# psoc6_01 register map
Vendor: Cypress Semiconductor; Series: PSoC6_01; File version: 1.0
CPU: CM4 r0p1, little endian, MPU, FPU, VTOR, 3 interrupt priority bits
Registers are 32-bit, read-write, reset 0x0 unless marked. A register's access mark holds for its fields unless they carry their own. Offsets are from the block's base; [hi:lo] are bit positions; {n}, {i} and the like mark numbered series; 'fields as' and 'values as' point back to an identical list.

## SCB0 (part 2 of 2) — Serial Communications Block (SPI/UART/I2C)
Base 0x40610000
Same registers: SCB{n} {0x40610000+0x10000*n} (n=1..8)
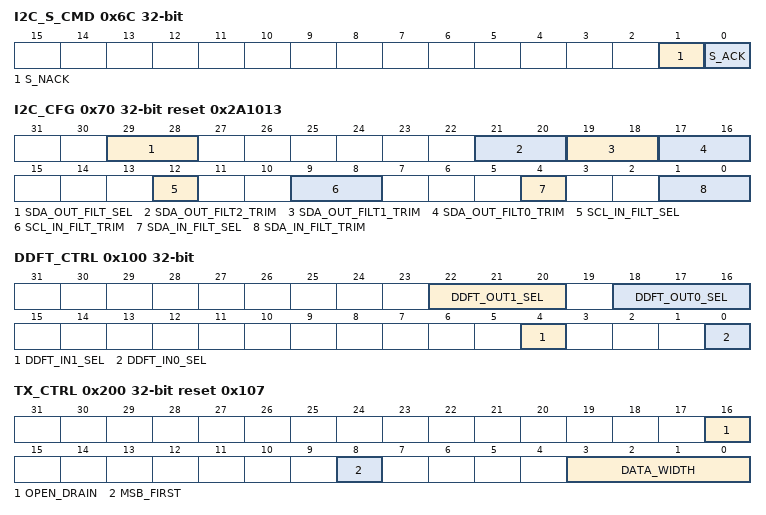
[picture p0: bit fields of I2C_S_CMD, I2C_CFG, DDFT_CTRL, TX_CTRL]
0x6C I2C_S_CMD — I2C slave command
  [1] S_NACK — When '1', attempt to transmit a negative acknowledgement (NACK). When this action is performed, the hardware sets this field to '0'. In EZ and CMD_RESP mode, this field should be set to '0' (it is only to be used in FIFO mode). This command has a higher priority than I2C_S_CMD.S_ACK, I2C_CTRL.S_READY_ADDR_ACK or I2C_CTRL.S_READY_DATA_ACK.
  [0] S_ACK — When '1', attempt to transmit an acknowledgement (ACK). When this action is performed, the hardware sets this field to '0'. In EZ and CMD_RESP mode, this field should be set to '0' (it is only to be used in FIFO mode).
0x70 I2C_CFG reset 0x2A1013 — I2C configuration
  [29:28] SDA_OUT_FILT_SEL
  [21:20] SDA_OUT_FILT2_TRIM — Trim bits for 'i2c_sda_out' 50 ns filter 2. Not to be modified by the user
  [19:18] SDA_OUT_FILT1_TRIM — Trim bits for 'i2c_sda_out' 50 ns filter 1. Not to be modified by the user
  [17:16] SDA_OUT_FILT0_TRIM — Trim bits for 'i2c_sda_out' 50 ns filter 0. Not to be modified by the user
  [12] SCL_IN_FILT_SEL
  [9:8] SCL_IN_FILT_TRIM — Trim bits for 'i2c_scl_in' 50 ns filter. Not to be modified by the user
  [4] SDA_IN_FILT_SEL
  [1:0] SDA_IN_FILT_TRIM — Trim bits for 'i2c_sda_in' 50 ns filter. SDA_IN_FILT_TRIM[1] is used to enable I2CS_EC or SPIS_EC access to internal EZ memory. 1: enable clk_scb 0: disable clk_scb Before going to deepsleep this field should be set to 0. It should be re-enabled once the device is awoken and clk_hf[0] is at the desired frequency.
0x100 DDFT_CTRL — Digital DfT control
  [22:20] DDFT_OUT1_SEL — Specifies signal that is connected to 'ddft_out[1]' (digital DfT output signal 1): In I2C mode (CTRL.MODE=0), '0': Constant '0'. '1': 'clk_ff_sram'. '2': 'rst_i2c_n'. '3': 'rst_i2c_stop_n'. '4': 'i2c_sda_in_qual'. '5': 'i2c_sda_out'. '6': 'event_i2c_ec_wake_up_ddft' from I2CS_IC '7': Undefined. In SPI mode (CTRL.MODE=1), '0': Constant '0'. '1': 'spi_start_detect' '2': 'spi_stop_detect' '3'-'7': Undefined.
  [18:16] DDFT_OUT0_SEL — Specifies signal that is connected to 'ddft_out[0]' (digital DfT output signal 0): In I2C mode (CTRL.MODE=0), '0': Constant '0'. '1': 'ec_busy_pp'. '2': 'rst_i2c_start_stop_n'. '3': 'rst_i2c_start_stop_n'. '4': 'i2c_scl_in_qual'. '5': 'i2c_sda_out_prel'. '6'-'7': Undefined. in SPI mode (CTRL.MODE=1), '0': Constant '0'. '1': 'rst_spi_n' '2': 'rst_spi_stop_n' '3'-'7': Undefined.
  [4] DDFT_IN1_SEL — Specifies signal that is connected to 'ddft_in[1]' (digital DfT input signal 0): '0': not used '1': used as 'i2c_sda_in' in I2C mode, as 'spi_mosi_in' in SPI mode
  [0] DDFT_IN0_SEL — Specifies signal that is connected to 'ddft_in[0]' (digital DfT input signal 0): '0': not used '1': used as 'i2c_scl_in' in I2C mode, as 'spi_clk_in' in SPI mode
0x200 TX_CTRL reset 0x107 — Transmitter control
  [16] OPEN_DRAIN — Each IO cell 'xxx' has two associated SCB output signals 'xxx_out_en' and 'xxx_out'. This field determines how the SCB controls those two signals. Consult the GPIO chapter in the architecture TRM to understand how the pin drive modes behave when connected to SCBs. '0': Normal operation mode. In this operation mode 'xxx_out_en' output enable signal is typically constant '1' the 'xxx_out' output is the outputted value. In other words, in normal operation mode, the 'xxx_out' output is used to control the IO cell output value: 'xxx_out' is '0' to drive an IO cell output value of '0' and 'xxx_out' is '1' to drive an IO cell output value of '1'. '1': Open drain operation mode. In this operation mode 'xxx_out_en' output controls the outputted value. Typically the 'xxx_out' signal is a constant '0'. Thus when 'xxx_out_en' is '1' the line is driven low, but when 'xxx_out_en' is '0' the output is not driven. This requires that the line is driven high by an external device or pull-up resistor The open drain mode is supported for: - I2C mode this field must be set. - UART mode use this mode when a pull-up resistor is used on the TX line. - SPI mode this field must be set if there are multiple slaves driving MISO.
  [8] MSB_FIRST — Least significant bit first ('0') or most significant bit first ('1'). For I2C, this field should be '1'. For EZ and CMD_RESP this field must be set to '1'
  [3:0] DATA_WIDTH — Dataframe width. DATA_WIDTH + 1 is the amount of bits in a transmitted data frame. This number does not include start, parity and stop bits. For UART mode, the valid range is [3, 8]. For SPI, the valid range is [3, 15]. For I2C the only valid value is 7. In EZ and CMD_RESP mode (for both SPI and I2C), the only valid value is 7.
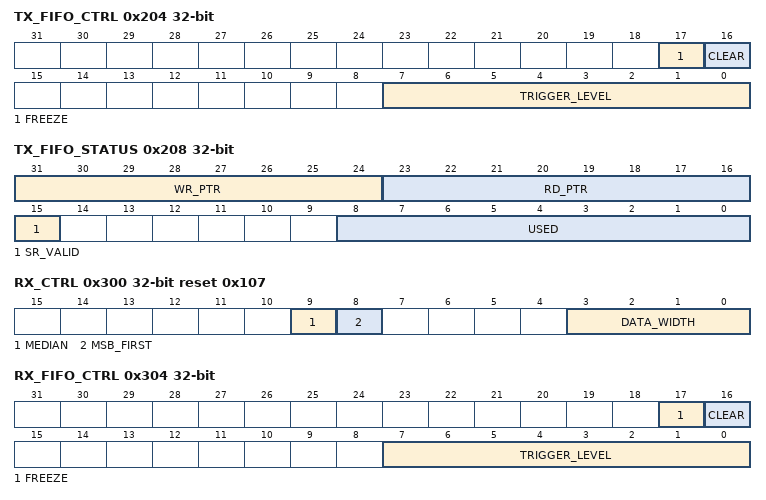
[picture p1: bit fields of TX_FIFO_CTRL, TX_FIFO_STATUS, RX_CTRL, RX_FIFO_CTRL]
0x204 TX_FIFO_CTRL — Transmitter FIFO control
  [17] FREEZE, [16] CLEAR, [7:0] TRIGGER_LEVEL
0x208 TX_FIFO_STATUS ro — Transmitter FIFO status
  [31:24] WR_PTR, [23:16] RD_PTR, [15] SR_VALID, [8:0] USED
0x240 TX_FIFO_WR wo — Transmitter FIFO write
  [15:0] DATA
0x300 RX_CTRL reset 0x107 — Receiver control
  [9] MEDIAN
  [8] MSB_FIRST — Least significant bit first ('0') or most significant bit first ('1'). For I2C, this field should be '1'. For EZ and CMD_RESP this field must be set to '1'
  [3:0] DATA_WIDTH
0x304 RX_FIFO_CTRL — Receiver FIFO control
  [17] FREEZE, [16] CLEAR, [7:0] TRIGGER_LEVEL
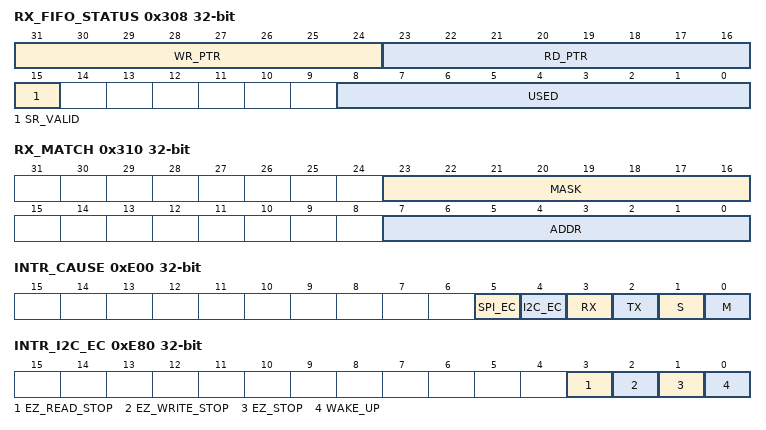
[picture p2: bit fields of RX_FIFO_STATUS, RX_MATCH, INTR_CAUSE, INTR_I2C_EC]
0x308 RX_FIFO_STATUS ro — Receiver FIFO status
  [31:24] WR_PTR, [23:16] RD_PTR, [15] SR_VALID, [8:0] USED
0x310 RX_MATCH — Slave address and mask
  [23:16] MASK, [7:0] ADDR
0x340 RX_FIFO_RD ro reset not defined — Receiver FIFO read
  [15:0] DATA — Data read from the receiver FIFO. Reading a data frame will remove the data frame from the FIFO; i.e. behavior is similar to that of a POP operation. Note that when CTRL.BYTE_MODE is '1', only DATA[7:0] are used. When in debug mode a read from this register behaves as a read from the SCB_RX_FIFO_RD_SILENT register. That is data will not be removed from the FIFO A read from an empty RX FIFO sets INTR_RX.UNDERFLOW to '1'.
0x344 RX_FIFO_RD_SILENT ro reset not defined — Receiver FIFO read silent
  [15:0] DATA
0xE00 INTR_CAUSE ro — Active clocked interrupt signal
  [5] SPI_EC — Externally clocked SPI interrupt active ('interrupt_spi_ec'): INTR_SPI_EC_MASKED != 0.
  [4] I2C_EC — Externally clock I2C interrupt active ('interrupt_i2c_ec'): INTR_I2C_EC_MASKED != 0.
  [3] RX — Receiver interrupt active ('interrupt_rx'): INTR_RX_MASKED != 0.
  [2] TX — Transmitter interrupt active ('interrupt_tx'): INTR_TX_MASKED != 0.
  [1] S — Slave interrupt active ('interrupt_slave'): INTR_S_MASKED != 0.
  [0] M — Master interrupt active ('interrupt_master'): INTR_M_MASKED != 0.
0xE80 INTR_I2C_EC — Externally clocked I2C interrupt request
  [3] EZ_READ_STOP — STOP detection after a read transfer occurred. Activated on the end of a read transfer (I2C STOP). This event is an indication that a buffer memory location has been read from. Only set for a slave request with an address match, in EZ and CMD_RESP modes, when EC_OP is '1'.
  [2] EZ_WRITE_STOP — STOP detection after a write transfer occurred. Activated on the end of a write transfer (I2C STOP). This event is an indication that a buffer memory location has been written to. For EZ mode: a transfer that only writes the base address does NOT activate this event. Only set for a slave request with an address match, in EZ and CMD_RESP modes, when EC_OP is '1'.
  [1] EZ_STOP — STOP detection. Activated on the end of a every transfer (I2C STOP). Only set for a slave request with an address match, in EZ and CMD_RESP modes, when EC_OP is '1'.
  [0] WAKE_UP — Wake up request. Active on incoming slave request (with address match). Only set when EC_AM is '1'.
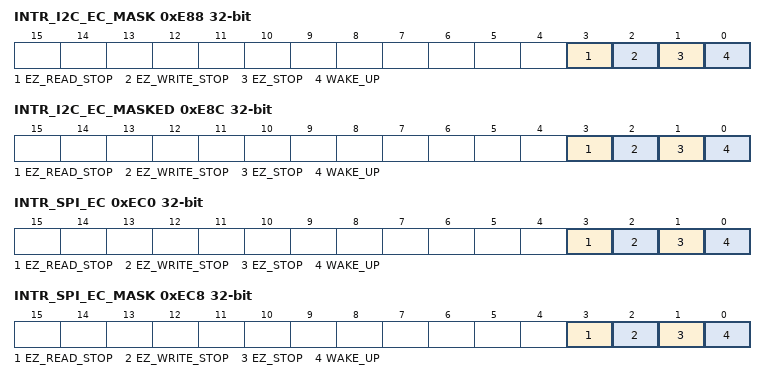
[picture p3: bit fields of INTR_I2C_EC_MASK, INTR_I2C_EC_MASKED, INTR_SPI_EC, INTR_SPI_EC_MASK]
0xE88 INTR_I2C_EC_MASK — Externally clocked I2C interrupt mask
  [3] EZ_READ_STOP — Mask bit for corresponding bit in interrupt request register.
  [2] EZ_WRITE_STOP — Mask bit for corresponding bit in interrupt request register.
  [1] EZ_STOP — Mask bit for corresponding bit in interrupt request register.
  [0] WAKE_UP — Mask bit for corresponding bit in interrupt request register.
0xE8C INTR_I2C_EC_MASKED ro — Externally clocked I2C interrupt masked
  [3] EZ_READ_STOP — Logical and of corresponding request and mask bits.
  [2] EZ_WRITE_STOP — Logical and of corresponding request and mask bits.
  [1] EZ_STOP — Logical and of corresponding request and mask bits.
  [0] WAKE_UP — Logical and of corresponding request and mask bits.
0xEC0 INTR_SPI_EC — Externally clocked SPI interrupt request
  [3] EZ_READ_STOP — STOP detection after a read transfer occurred. Activated on the end of a read transfer (SPI deselection). This event is an indication that a buffer memory location has been read from. Only set in EZ and CMD_RESP modes and when EC_OP is '1'.
  [2] EZ_WRITE_STOP — STOP detection after a write transfer occurred. Activated on the end of a write transfer (SPI deselection). This event is an indication that a buffer memory location has been written to. For EZ mode: a transfer that only writes the base address does NOT activate this event. Only set in EZ and CMD_RESP modes and when EC_OP is '1'.
  [1] EZ_STOP — STOP detection. Activated on the end of a every transfer (SPI deselection). Only set in EZ and CMD_RESP mode and when EC_OP is '1'.
  [0] WAKE_UP — Wake up request. Active on incoming slave request. Only set when EC_AM is '1'.
0xEC8 INTR_SPI_EC_MASK — Externally clocked SPI interrupt mask
  fields as INTR_I2C_EC_MASK
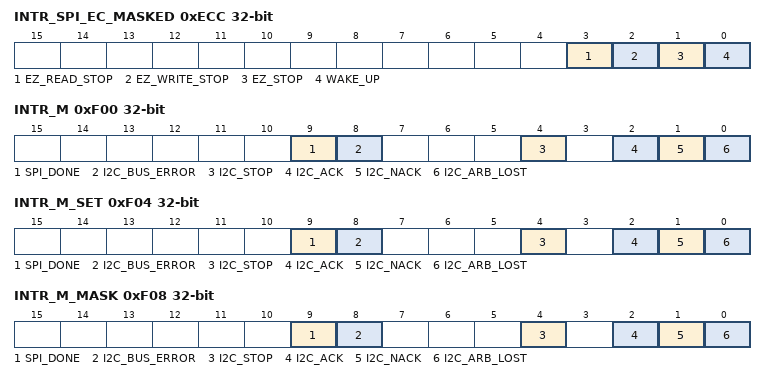
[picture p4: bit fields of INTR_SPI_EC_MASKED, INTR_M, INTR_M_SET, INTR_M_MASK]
0xECC INTR_SPI_EC_MASKED ro — Externally clocked SPI interrupt masked
  fields as INTR_I2C_EC_MASKED
0xF00 INTR_M — Master interrupt request
  [9] SPI_DONE, [8] I2C_BUS_ERROR, [4] I2C_STOP, [2] I2C_ACK, [1] I2C_NACK, [0] I2C_ARB_LOST
0xF04 INTR_M_SET — Master interrupt set request
  [9] SPI_DONE — Write with '1' to set corresponding bit in interrupt request register.
  [8] I2C_BUS_ERROR — Write with '1' to set corresponding bit in interrupt request register.
  [4] I2C_STOP — Write with '1' to set corresponding bit in interrupt request register.
  [2] I2C_ACK — Write with '1' to set corresponding bit in interrupt request register.
  [1] I2C_NACK — Write with '1' to set corresponding bit in interrupt request register.
  [0] I2C_ARB_LOST — Write with '1' to set corresponding bit in interrupt request register.
0xF08 INTR_M_MASK — Master interrupt mask
  [9] SPI_DONE — Mask bit for corresponding bit in interrupt request register.
  [8] I2C_BUS_ERROR — Mask bit for corresponding bit in interrupt request register.
  [4] I2C_STOP — Mask bit for corresponding bit in interrupt request register.
  [2] I2C_ACK — Mask bit for corresponding bit in interrupt request register.
  [1] I2C_NACK — Mask bit for corresponding bit in interrupt request register.
  [0] I2C_ARB_LOST — Mask bit for corresponding bit in interrupt request register.
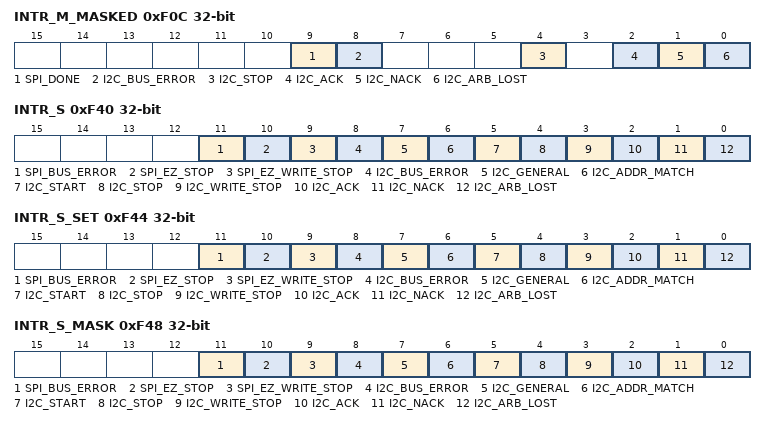
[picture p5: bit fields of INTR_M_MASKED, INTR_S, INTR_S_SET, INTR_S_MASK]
0xF0C INTR_M_MASKED ro — Master interrupt masked request
  [9] SPI_DONE — Logical and of corresponding request and mask bits.
  [8] I2C_BUS_ERROR — Logical and of corresponding request and mask bits.
  [4] I2C_STOP — Logical and of corresponding request and mask bits.
  [2] I2C_ACK — Logical and of corresponding request and mask bits.
  [1] I2C_NACK — Logical and of corresponding request and mask bits.
  [0] I2C_ARB_LOST — Logical and of corresponding request and mask bits.
0xF40 INTR_S — Slave interrupt request
  [11] SPI_BUS_ERROR — SPI slave deselected at an unexpected time in the SPI transfer. Firmware may decide to clear the TX and RX FIFOs in case of this error.
  [10] SPI_EZ_STOP
  [9] SPI_EZ_WRITE_STOP
  [8] I2C_BUS_ERROR — I2C slave bus error (unexpected detection of START or STOP condition). This should not occur, it represents erroneous I2C bus behavior. In case of a bus error, the I2C slave state machine abort the ongoing transfer. Firmware may decide to clear the TX and RX FIFOs in case of this error.
  [7] I2C_GENERAL — I2C slave general call address received. If CTRL.ADDR_ACCEPT is set the received address 0x00 (including the R/W bit) is available in the RX FIFO. In the case of externally clocked address matching (CTRL.EC_AM_MODE is '1') and internally clocked operation (CTRL.EC_OP_MODE is '0'), this field is set when the event is detected.
  [6] I2C_ADDR_MATCH
  [5] I2C_START — I2C slave START received. Set to '1', when START or REPEATED START event is detected. In the case of externally clocked address matching (CTRL.EC_AM_MODE is '1') AND clock stretching is performed (till the internally clocked logic takes over) (I2C_CTRL.S_NOT_READY_ADDR_NACK is '0'), this field is NOT set. Firmware should use INTR_S_EC.WAKE_UP, INTR_S.I2C_ADDR_MATCH and INTR_S.I2C_GENERAL.
  [4] I2C_STOP
  [3] I2C_WRITE_STOP — I2C STOP event for I2C write transfer intended for this slave (address matching is performed). Set to '1', when STOP or REPEATED START event is detected. The REPEATED START event is included in this interrupt cause such that the I2C transfers separated by a REPEATED START can be distinguished and potentially treated separately by the firmware. Note that the second I2C transfer (after a REPEATED START) may be to a different slave address. Note that a I2C write address intended for the slave (address is matching and a it is a write transfer) will result in a I2C_WRITE_STOP event independent of whether the I2C address is ACK'd or NACK'd. In EZ mode, the event is detected only on I2C write transfers that have EZ data written to the memory structure (an I2C write transfer that only communicates an I2C address and EZ base address, will not result in this event being detected).
  [2] I2C_ACK
  [1] I2C_NACK
  [0] I2C_ARB_LOST — I2C slave lost arbitration: the value driven on the SDA line is not the same as the value observed on the SDA line (while the SCL line is '1'). This should not occur, it represents erroneous I2C bus behavior. In case of lost arbitration, the I2C slave state machine aborts the ongoing transfer. SW may decide to clear the TX and RX FIFOs in case of this error.
0xF44 INTR_S_SET — Slave interrupt set request
  [11] SPI_BUS_ERROR — Write with '1' to set corresponding bit in interrupt request register.
  [10] SPI_EZ_STOP — Write with '1' to set corresponding bit in interrupt request register.
  [9] SPI_EZ_WRITE_STOP — Write with '1' to set corresponding bit in interrupt request register.
  [8] I2C_BUS_ERROR — Write with '1' to set corresponding bit in interrupt request register.
  [7] I2C_GENERAL — Write with '1' to set corresponding bit in interrupt request register.
  [6] I2C_ADDR_MATCH — Write with '1' to set corresponding bit in interrupt request register.
  [5] I2C_START — Write with '1' to set corresponding bit in interrupt request register.
  [4] I2C_STOP — Write with '1' to set corresponding bit in interrupt request register.
  [3] I2C_WRITE_STOP — Write with '1' to set corresponding bit in interrupt request register.
  [2] I2C_ACK — Write with '1' to set corresponding bit in interrupt request register.
  [1] I2C_NACK — Write with '1' to set corresponding bit in interrupt request register.
  [0] I2C_ARB_LOST — Write with '1' to set corresponding bit in interrupt request register.
0xF48 INTR_S_MASK — Slave interrupt mask
  [11] SPI_BUS_ERROR — Mask bit for corresponding bit in interrupt request register.
  [10] SPI_EZ_STOP — Mask bit for corresponding bit in interrupt request register.
  [9] SPI_EZ_WRITE_STOP — Mask bit for corresponding bit in interrupt request register.
  [8] I2C_BUS_ERROR — Mask bit for corresponding bit in interrupt request register.
  [7] I2C_GENERAL — Mask bit for corresponding bit in interrupt request register.
  [6] I2C_ADDR_MATCH — Mask bit for corresponding bit in interrupt request register.
  [5] I2C_START — Mask bit for corresponding bit in interrupt request register.
  [4] I2C_STOP — Mask bit for corresponding bit in interrupt request register.
  [3] I2C_WRITE_STOP — Mask bit for corresponding bit in interrupt request register.
  [2] I2C_ACK — Mask bit for corresponding bit in interrupt request register.
  [1] I2C_NACK — Mask bit for corresponding bit in interrupt request register.
  [0] I2C_ARB_LOST — Mask bit for corresponding bit in interrupt request register.
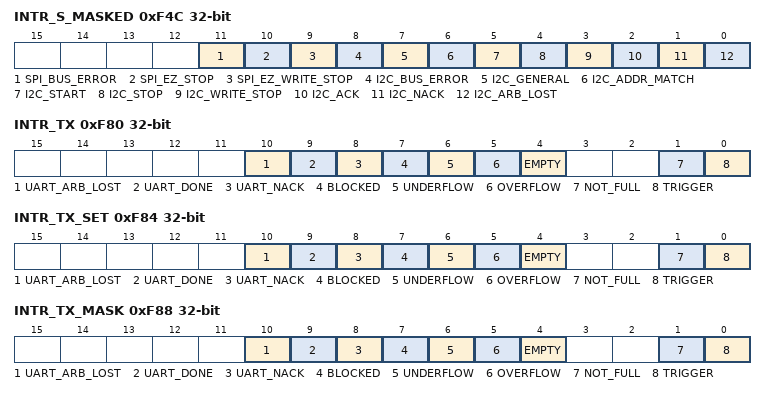
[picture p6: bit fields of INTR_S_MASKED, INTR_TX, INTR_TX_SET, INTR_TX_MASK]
0xF4C INTR_S_MASKED ro — Slave interrupt masked request
  [11] SPI_BUS_ERROR — Logical and of corresponding request and mask bits.
  [10] SPI_EZ_STOP — Logical and of corresponding request and mask bits.
  [9] SPI_EZ_WRITE_STOP — Logical and of corresponding request and mask bits.
  [8] I2C_BUS_ERROR — Logical and of corresponding request and mask bits.
  [7] I2C_GENERAL — Logical and of corresponding request and mask bits.
  [6] I2C_ADDR_MATCH — Logical and of corresponding request and mask bits.
  [5] I2C_START — Logical and of corresponding request and mask bits.
  [4] I2C_STOP — Logical and of corresponding request and mask bits.
  [3] I2C_WRITE_STOP — Logical and of corresponding request and mask bits.
  [2] I2C_ACK — Logical and of corresponding request and mask bits.
  [1] I2C_NACK — Logical and of corresponding request and mask bits.
  [0] I2C_ARB_LOST — Logical and of corresponding request and mask bits.
0xF80 INTR_TX — Transmitter interrupt request
  [10] UART_ARB_LOST — UART lost arbitration: the value driven on the TX line is not the same as the value observed on the RX line. This condition event is usefull when transmitter and receiver share a TX/RX line. This is the case in LIN or SmartCard modes.
  [9] UART_DONE — UART transmitter done event. This happens when the SCB is done transferring all data in the TX FIFO, and the last stop field is transmitted (both TX FIFO and transmit shifter register are empty).
  [8] UART_NACK
  [7] BLOCKED — CPU write can not get access to the EZ memory (EZ data access), due to an externally clocked EZ access.
  [6] UNDERFLOW — Attempt to read from an empty TX FIFO. This happens when the SCB is ready to transfer data and EMPTY is '1'. Only used in FIFO mode.
  [5] OVERFLOW
  [4] EMPTY
  [1] NOT_FULL
  [0] TRIGGER
0xF84 INTR_TX_SET — Transmitter interrupt set request
  [10] UART_ARB_LOST — Write with '1' to set corresponding bit in interrupt request register.
  [9] UART_DONE — Write with '1' to set corresponding bit in interrupt request register.
  [8] UART_NACK — Write with '1' to set corresponding bit in interrupt request register.
  [7] BLOCKED — Write with '1' to set corresponding bit in interrupt request register.
  [6] UNDERFLOW — Write with '1' to set corresponding bit in interrupt request register.
  [5] OVERFLOW — Write with '1' to set corresponding bit in interrupt request register.
  [4] EMPTY — Write with '1' to set corresponding bit in interrupt request register.
  [1] NOT_FULL — Write with '1' to set corresponding bit in interrupt request register.
  [0] TRIGGER — Write with '1' to set corresponding bit in interrupt request register.
0xF88 INTR_TX_MASK — Transmitter interrupt mask
  [10] UART_ARB_LOST — Mask bit for corresponding bit in interrupt request register.
  [9] UART_DONE — Mask bit for corresponding bit in interrupt request register.
  [8] UART_NACK — Mask bit for corresponding bit in interrupt request register.
  [7] BLOCKED — Mask bit for corresponding bit in interrupt request register.
  [6] UNDERFLOW — Mask bit for corresponding bit in interrupt request register.
  [5] OVERFLOW — Mask bit for corresponding bit in interrupt request register.
  [4] EMPTY — Mask bit for corresponding bit in interrupt request register.
  [1] NOT_FULL — Mask bit for corresponding bit in interrupt request register.
  [0] TRIGGER — Mask bit for corresponding bit in interrupt request register.
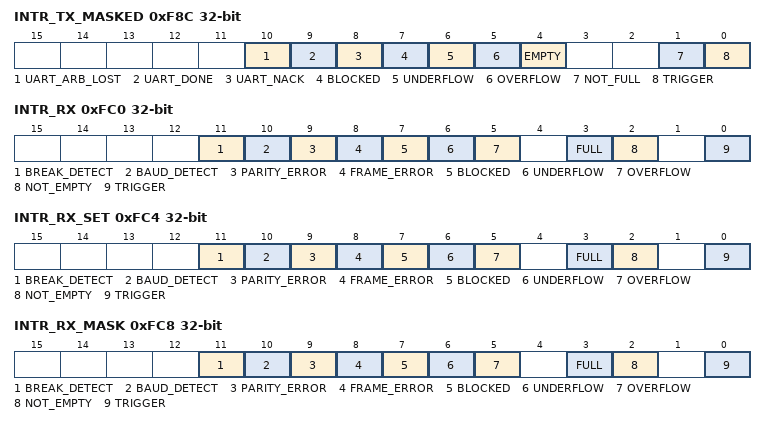
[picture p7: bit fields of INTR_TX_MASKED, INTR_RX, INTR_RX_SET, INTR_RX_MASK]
0xF8C INTR_TX_MASKED ro — Transmitter interrupt masked request
  [10] UART_ARB_LOST — Logical and of corresponding request and mask bits.
  [9] UART_DONE — Logical and of corresponding request and mask bits.
  [8] UART_NACK — Logical and of corresponding request and mask bits.
  [7] BLOCKED — Logical and of corresponding request and mask bits.
  [6] UNDERFLOW — Logical and of corresponding request and mask bits.
  [5] OVERFLOW — Logical and of corresponding request and mask bits.
  [4] EMPTY — Logical and of corresponding request and mask bits.
  [1] NOT_FULL — Logical and of corresponding request and mask bits.
  [0] TRIGGER — Logical and of corresponding request and mask bits.
0xFC0 INTR_RX — Receiver interrupt request
  [11] BREAK_DETECT — Break detection is successful: the line is '0' for UART_RX_CTRL.BREAK_WIDTH + 1 bit period. Can occur at any time to address unanticipated break fields; i.e. 'break-in-data' is supported. This feature is supported for the UART standard and LIN submodes. For the UART standard submodes, ongoing receipt of data frames is NOT affected; i.e. Firmware is expected to take the proper action. For the LIN submode, possible ongoing receipt of a data frame is stopped and the (partially) received data frame is dropped and baud rate detection is started. Set to '1', when event is detected. Write with '1' to clear bit.
  [10] BAUD_DETECT — LIN baudrate detection is completed. The receiver software uses the UART_RX_STATUS.BR_COUNTER value to set the clk_scb to guarantee successful receipt of the first LIN data frame (Protected Identifier Field) after the synchronization byte.
  [9] PARITY_ERROR — UART Parity error in received data frame. If UART_RX_CTL.DROP_ON_PARITY_ERROR is '1', the received frame is dropped. If UART_RX_CTL.DROP_ON_PARITY_ERROR is '0', the received frame is send to the RX FIFO. In SmartCard submode, negatively acknowledged data frames generate a parity error. Note that Firmware can only identify the erroneous data frame in the RX FIFO if it is fast enough to read the data frame before the hardware writes a next data frame into the RX FIFO.
  [8] FRAME_ERROR — UART Frame error in received data frame. This can be either a start or stop bit(s) error: Start bit error: after the detection of the beginning of a start bit period (RX line changes from '1' to '0'), the middle of the start bit period is sampled erroneously (RX line is '1'). Note: a start bit error is detected BEFORE a data frame is received. Stop bit error: the RX line is sampled as '0', but a '1' was expected. Note: a stop bit error may result in failure to receive successive data frame(s). Note: a stop bit error is detected AFTER a data frame is received. A stop bit error is detected after a data frame is received, and the UART_RX_CTL.DROP_ON_FRAME_ERROR field specifies whether the received frame is dropped or send to the RX FIFO. If UART_RX_CTL.DROP_ON_FRAME_ERROR is '1', the received data frame is dropped. If UART_RX_CTL.DROP_ON_FRAME_ERROR is '0', the received data frame is send to the RX FIFO. Note that Firmware can only identify the erroneous data frame in the RX FIFO if it is fast enough to read the data frame before the hardware writes a next data frame into the RX FIFO; i.e. the RX FIFO does not have error flags to tag erroneous data frames.
  [7] BLOCKED — CPU read transfer can not get access to the EZ memory (EZ_DATA accesses), due to an externally clocked EZ access.
  [6] UNDERFLOW
  [5] OVERFLOW
  [3] FULL
  [2] NOT_EMPTY
  [0] TRIGGER
0xFC4 INTR_RX_SET — Receiver interrupt set request
  [11] BREAK_DETECT — Write with '1' to set corresponding bit in interrupt status register.
  [10] BAUD_DETECT — Write with '1' to set corresponding bit in interrupt status register.
  [9] PARITY_ERROR — Write with '1' to set corresponding bit in interrupt status register.
  [8] FRAME_ERROR — Write with '1' to set corresponding bit in interrupt status register.
  [7] BLOCKED — Write with '1' to set corresponding bit in interrupt status register.
  [6] UNDERFLOW — Write with '1' to set corresponding bit in interrupt status register.
  [5] OVERFLOW — Write with '1' to set corresponding bit in interrupt status register.
  [3] FULL — Write with '1' to set corresponding bit in interrupt status register.
  [2] NOT_EMPTY — Write with '1' to set corresponding bit in interrupt status register.
  [0] TRIGGER — Write with '1' to set corresponding bit in interrupt request register.
0xFC8 INTR_RX_MASK — Receiver interrupt mask
  [11] BREAK_DETECT — Mask bit for corresponding bit in interrupt request register.
  [10] BAUD_DETECT — Mask bit for corresponding bit in interrupt request register.
  [9] PARITY_ERROR — Mask bit for corresponding bit in interrupt request register.
  [8] FRAME_ERROR — Mask bit for corresponding bit in interrupt request register.
  [7] BLOCKED — Mask bit for corresponding bit in interrupt request register.
  [6] UNDERFLOW — Mask bit for corresponding bit in interrupt request register.
  [5] OVERFLOW — Mask bit for corresponding bit in interrupt request register.
  [3] FULL — Mask bit for corresponding bit in interrupt request register.
  [2] NOT_EMPTY — Mask bit for corresponding bit in interrupt request register.
  [0] TRIGGER — Mask bit for corresponding bit in interrupt request register.
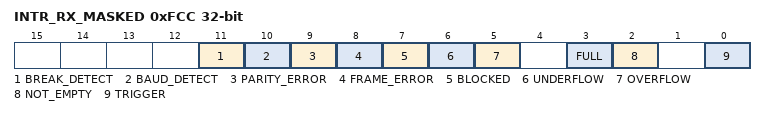
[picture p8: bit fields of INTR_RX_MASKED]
0xFCC INTR_RX_MASKED ro — Receiver interrupt masked request
  [11] BREAK_DETECT — Logical and of corresponding request and mask bits.
  [10] BAUD_DETECT — Logical and of corresponding request and mask bits.
  [9] PARITY_ERROR — Logical and of corresponding request and mask bits.
  [8] FRAME_ERROR — Logical and of corresponding request and mask bits.
  [7] BLOCKED — Logical and of corresponding request and mask bits.
  [6] UNDERFLOW — Logical and of corresponding request and mask bits.
  [5] OVERFLOW — Logical and of corresponding request and mask bits.
  [3] FULL — Logical and of corresponding request and mask bits.
  [2] NOT_EMPTY — Logical and of corresponding request and mask bits.
  [0] TRIGGER — Logical and of corresponding request and mask bits.
